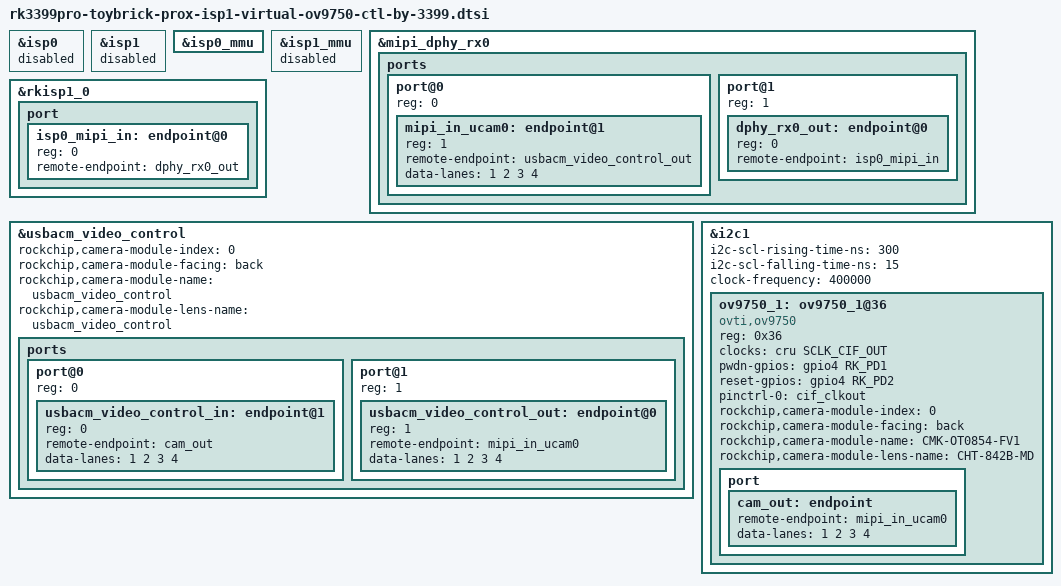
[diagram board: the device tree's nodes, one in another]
/*
 * Copyright (c) 2018 Fuzhou Rockchip Electronics Co., Ltd
 *
 * This file is dual-licensed: you can use it either under the terms
 * of the GPL or the X11 license, at your option. Note that this dual
 * licensing only applies to this file, and not this project as a
 * whole.
 *
 *  a) This file is free software; you can redistribute it and/or
 *     modify it under the terms of the GNU General Public License as
 *     published by the Free Software Foundation; either version 2 of the
 *     License, or (at your option) any later version.
 *
 *     This file is distributed in the hope that it will be useful,
 *     but WITHOUT ANY WARRANTY; without even the implied warranty of
 *     MERCHANTABILITY or FITNESS FOR A PARTICULAR PURPOSE.  See the
 *     GNU General Public License for more details.
 *
 * Or, alternatively,
 *
 *  b) Permission is hereby granted, free of charge, to any person
 *     obtaining a copy of this software and associated documentation
 *     files (the "Software"), to deal in the Software without
 *     restriction, including without limitation the rights to use,
 *     copy, modify, merge, publish, distribute, sublicense, and/or
 *     sell copies of the Software, and to permit persons to whom the
 *     Software is furnished to do so, subject to the following
 *     conditions:
 *
 *     The above copyright notice and this permission notice shall be
 *     included in all copies or substantial portions of the Software.
 *
 *     THE SOFTWARE IS PROVIDED "AS IS", WITHOUT WARRANTY OF ANY KIND,
 *     EXPRESS OR IMPLIED, INCLUDING BUT NOT LIMITED TO THE WARRANTIES
 *     OF MERCHANTABILITY, FITNESS FOR A PARTICULAR PURPOSE AND
 *     NONINFRINGEMENT. IN NO EVENT SHALL THE AUTHORS OR COPYRIGHT
 *     HOLDERS BE LIABLE FOR ANY CLAIM, DAMAGES OR OTHER LIABILITY,
 *     WHETHER IN AN ACTION OF CONTRACT, TORT OR OTHERWISE, ARISING
 *     FROM, OUT OF OR IN CONNECTION WITH THE SOFTWARE OR THE USE OR
 *     OTHER DEALINGS IN THE SOFTWARE.
 */
&isp0 {
	status = "disabled";
};

&isp1 {
	status = "disabled";
};

&isp0_mmu {
	status = "okay";
};

&isp1_mmu {
	status = "disabled";
};

&mipi_dphy_rx0 {
	status = "okay";

	ports {
		#address-cells = <1>;
		#size-cells = <0>;

		port@0 {
			reg = <0>;
			#address-cells = <1>;
			#size-cells = <0>;

			mipi_in_ucam0: endpoint@1 {
				reg = <1>;
				remote-endpoint = <&usbacm_video_control_out>;
				data-lanes = <1 2 3 4>;
			};
		};

		port@1 {
			reg = <1>;
			#address-cells = <1>;
			#size-cells = <0>;

			dphy_rx0_out: endpoint@0 {
				reg = <0>;
				remote-endpoint = <&isp0_mipi_in>;
			};
		};
	};
};

&rkisp1_0 {
	status = "okay";

	port {
		#address-cells = <1>;
		#size-cells = <0>;

		isp0_mipi_in: endpoint@0 {
			reg = <0>;
			remote-endpoint = <&dphy_rx0_out>;
		};
	};
};

&usbacm_video_control {
	status = "okay";
	rockchip,camera-module-index = <0>;
	rockchip,camera-module-facing = "back";
	rockchip,camera-module-name = "usbacm_video_control";
	rockchip,camera-module-lens-name = "usbacm_video_control";

	ports {
		#address-cells = <1>;
		#size-cells = <0>;

		port@0 {
			reg = <0>;
			#address-cells = <1>;
			#size-cells = <0>;

			usbacm_video_control_in: endpoint@1 {
				reg = <0>;
				remote-endpoint = <&cam_out>;
				data-lanes = <1 2 3 4>;
			};
		};

		port@1 {
			reg = <1>;
			#address-cells = <1>;
			#size-cells = <0>;

			usbacm_video_control_out: endpoint@0 {
				reg = <1>;
				remote-endpoint = <&mipi_in_ucam0>;
				data-lanes = <1 2 3 4>;
			};
		};
	};
};

&i2c1 {
	status = "okay";
	i2c-scl-rising-time-ns = <300>;
	i2c-scl-falling-time-ns = <15>;
	clock-frequency=<400000>;
	ov9750_1: ov9750_1@36 {//or 0x10  0x36
		compatible = "ovti,ov9750";
		reg = <0x36>;
		clocks = <&cru SCLK_CIF_OUT>;
		clock-names = "xvclk";
		//pwdn-gpios = <&gpio3 RK_PD7 GPIO_ACTIVE_HIGH>;
		//reset-gpios = <&gpio3 RK_PD2 GPIO_ACTIVE_HIGH>;

		pwdn-gpios = <&gpio4 RK_PD1 GPIO_ACTIVE_HIGH>;
		reset-gpios = <&gpio4 RK_PD2 GPIO_ACTIVE_HIGH>;
		pinctrl-names = "default";
		pinctrl-0 = <&cif_clkout>;
		rockchip,camera-module-index = <0>;
		rockchip,camera-module-facing = "back";
		rockchip,camera-module-name = "CMK-OT0854-FV1";
		rockchip,camera-module-lens-name = "CHT-842B-MD";
		port {
			cam_out: endpoint {
				remote-endpoint = <&mipi_in_ucam0>;
				data-lanes = <1 2 3 4>;
			};
		};
	};
};

